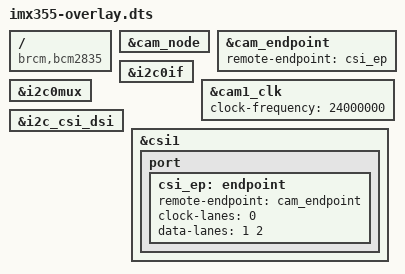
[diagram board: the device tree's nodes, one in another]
// SPDX-License-Identifier: GPL-2.0-only
// Definitions for IMX355 camera module on VC I2C bus
/dts-v1/;
/plugin/;

#include <dt-bindings/gpio/gpio.h>

/{
	compatible = "brcm,bcm2835";

	fragment@0 {
		target = <&i2c0if>;
		__overlay__ {
			status = "okay";
		};
	};

	clk_frag: fragment@1 {
		target = <&cam1_clk>;
		__overlay__ {
			status = "okay";
			clock-frequency = <24000000>;
		};
	};

	fragment@2 {
		target = <&i2c0mux>;
		__overlay__ {
			status = "okay";
		};
	};

	i2c_frag: fragment@100 {
		target = <&i2c_csi_dsi>;
		__overlay__ {
			#address-cells = <1>;
			#size-cells = <0>;
			status = "okay";

			#include "imx355.dtsi"
		};
	};

	csi_frag: fragment@101 {
		target = <&csi1>;
		csi: __overlay__ {
			status = "okay";

			port {
				csi_ep: endpoint {
					remote-endpoint = <&cam_endpoint>;
					clock-lanes = <0>;
					data-lanes = <1 2>;
				};
			};
		};
	};

	fragment@102 {
		target = <&csi1>;
		__dormant__ {
			compatible = "brcm,bcm2835-unicam-legacy";
		};
	};

	fragment@201 {
		target = <&csi_ep>;
		__dormant__ {
			data-lanes = <1 2 3 4>;
		};
	};

	fragment@202 {
		target = <&cam_endpoint>;
		__dormant__ {
			data-lanes = <1 2 3 4>;
			link-frequencies =
					/bits/ 64 <360000000>;
		};
	};

	__overrides__ {
		rotation = <&cam_node>,"rotation:0";
		orientation = <&cam_node>,"orientation:0";
		media-controller = <0>,"!102";
		cam0 = <&i2c_frag>, "target:0=",<&i2c_csi_dsi0>,
		       <&csi_frag>, "target:0=",<&csi0>,
		       <&clk_frag>, "target:0=",<&cam0_clk>,
		       <&cam_node>, "clocks:0=",<&cam0_clk>,
		       <&cam_node>, "avdd-supply:0=",<&cam0_reg>;
		4lane = <0>, "+201+202";
	};
};

&cam_node {
	status = "okay";
};

&cam_endpoint {
	remote-endpoint = <&csi_ep>;
};
